# tviic2d6mddr register map
Vendor: Cypress Semiconductor; Series: tviic2d6mddr; File version: 1.0
CPU: CM7 r0p1, little endian, MPU, FPU, VTOR, 3 interrupt priority bits
Registers are 32-bit, read-write, reset 0x0 unless marked. A register's access mark holds for its fields unless they carry their own. Offsets are from the block's base; [hi:lo] are bit positions; lines under a group give offsets from that group; {n}, {i} and the like mark numbered series; 'fields as' and 'values as' point back to an identical list.

## VIDEOSS0 (part 17 of 18) — Video and Graphics Subsystem IP
Base 0x40A00000
0xF0000 INFRA group — AXI Infrastructure
  0x00 VRPU group — VRPU configuration.
    0x00 RD0_CTL ro — VRAM protection for read requests with ID=0 (not used).
      [9:8] PRIO
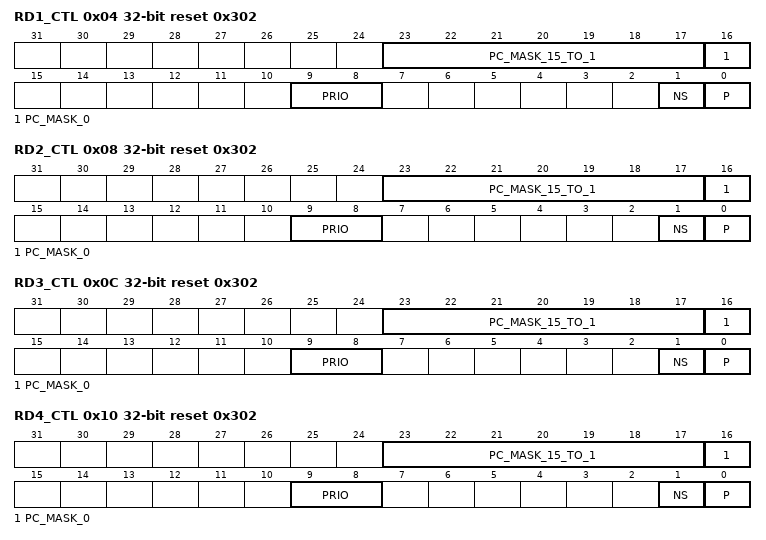
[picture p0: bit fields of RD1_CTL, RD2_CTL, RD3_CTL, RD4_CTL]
    0x04 RD1_CTL reset 0x302 — VRAM protection for read requests with ID=1 (fetchdecode0).
      [23:17] PC_MASK_15_TO_1 — Protection context mask for protection contexts '7' downto '1' (note: field name prefix '15_TO_1' is inconsistent due to backward compatibility). Bit PC_MASK_15_TO_1[i] indicates if the GFX_MPU_RDx RD_CTL.PC[3:0] protection context field can be set to the value 'i+1': - PC_MASK_15_TO_1[i] is '0': GFX_MPU_RDx RD_CTL.PC[3:0] can NOT be set to 'i+1'; and PC[3:0] is not changed. If the protection context of the write transfer is '0', protection is not applied and PC[3:0] can be changed. - PC_MASK_15_TO_1[i] is '1': GFX_MPU_RDx RD_CTL.PC[3:0] can be set to 'i+1'.
      [16] PC_MASK_0 ro — Protection context mask for protection context '0'. This field is a constant '0'.
      [9:8] PRIO — Device wide bus arbitration priority setting ('0': highest priority, '3': lowest priority). Masters with the same priority setting form a 'priority group'. Within a 'priority group', roundrobin arbitration is performed.
      [1] NS — Security setting ('0': secure mode; '1': non-secure mode).
      [0] P — Privileged setting ('0': user mode; '1': privileged mode).
    0x08 RD2_CTL reset 0x302 — VRAM protection for read requests with ID=2 (fetchlayer0).
      [23:17] PC_MASK_15_TO_1 — See RD1_CTL.PC_MASK_15_TO_1.
      [16] PC_MASK_0 ro — See RD1_CTL.PC_MASK_0.
      [9:8] PRIO — See RD1_CTL.PRIO.
      [1] NS — See RD1_CTL.NS.
      [0] P — See RD1_CTL.P.
    0x0C RD3_CTL reset 0x302 — VRAM protection for read requests with ID=3 (fetchwarp1).
      fields as INFRA.VRPU.RD2_CTL
    0x10 RD4_CTL reset 0x302 — VRAM protection for read requests with ID=4 (fetcheco1).
      fields as INFRA.VRPU.RD2_CTL
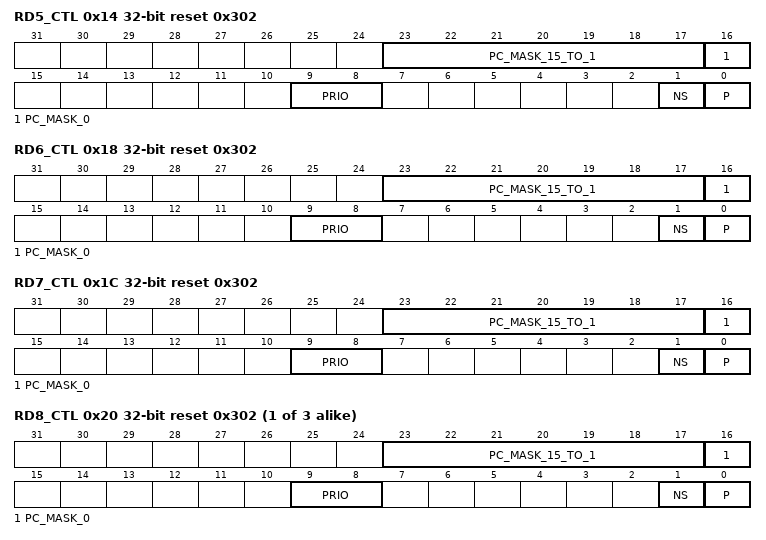
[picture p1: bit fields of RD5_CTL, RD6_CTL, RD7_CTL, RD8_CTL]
    0x14 RD5_CTL reset 0x302 — VRAM protection for read requests with ID=5 (fetcheco4).
      fields as INFRA.VRPU.RD2_CTL
    0x18 RD6_CTL reset 0x302 — VRAM protection for read requests with ID=6 (fetchlayer1).
      fields as INFRA.VRPU.RD2_CTL
    0x1C RD7_CTL reset 0x302 — VRAM protection for read requests with ID=7 (fetchdecode4).
      fields as INFRA.VRPU.RD2_CTL
    {0x0+4k} RD{k}_CTL reset 0x302 (k=8..10) — VRAM protection for read requests with ID={k} (fetchblit0/1/2).
      fields as INFRA.VRPU.RD2_CTL
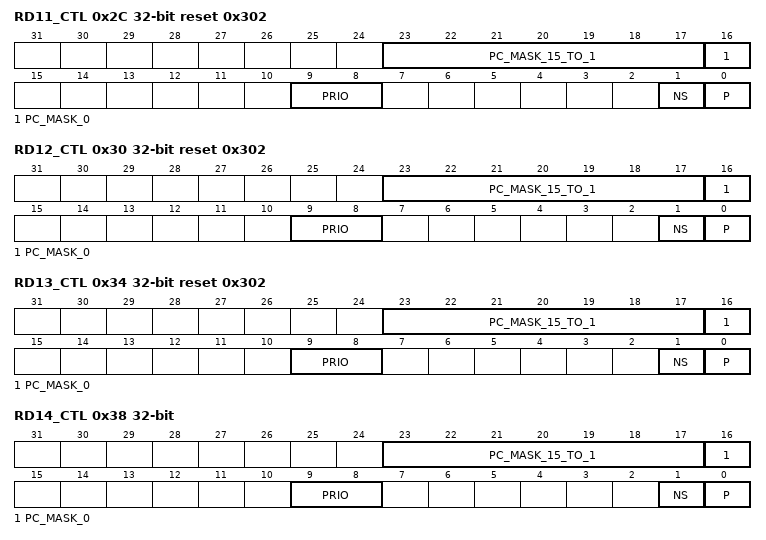
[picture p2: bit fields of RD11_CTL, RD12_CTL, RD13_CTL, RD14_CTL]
    0x2C RD11_CTL reset 0x302 — VRAM protection for read requests with ID=11 (cmdseqrd).
      fields as INFRA.VRPU.RD2_CTL
    0x30 RD12_CTL reset 0x302 — VRAM protection for read requests with ID=12 (drawengrd).
      fields as INFRA.VRPU.RD2_CTL
    0x34 RD13_CTL reset 0x302 — VRAM protection for read requests with ID=13 (jpegdecrd).
      fields as INFRA.VRPU.RD2_CTL
    0x38 RD14_CTL ro — VRAM protection for read requests with ID=14 (not used).
      [23:17] PC_MASK_15_TO_1, [16] PC_MASK_0, [9:8] PRIO, [1] NS, [0] P
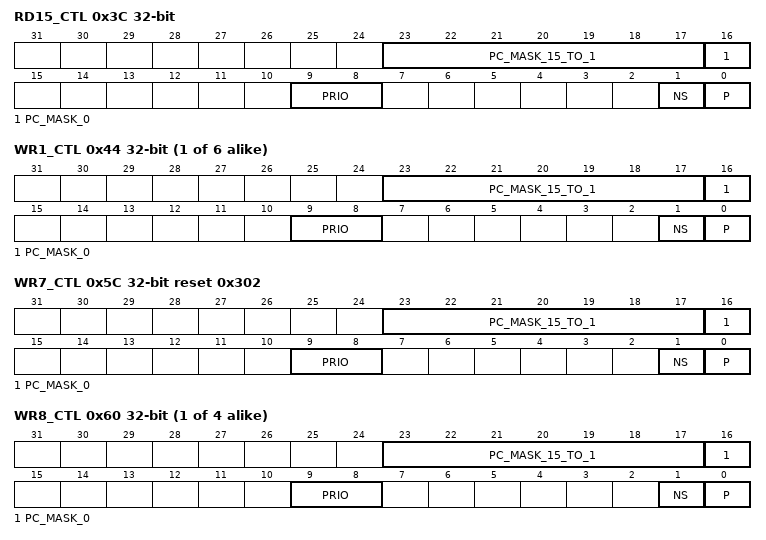
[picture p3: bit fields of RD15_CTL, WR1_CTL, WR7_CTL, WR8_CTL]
    0x3C RD15_CTL ro — VRAM protection for read requests with ID=15 (not used).
      [23:17] PC_MASK_15_TO_1, [16] PC_MASK_0, [9:8] PRIO, [1] NS, [0] P
    0x40 WR0_CTL ro — VRAM protection for write requests with ID=0 (not used).
      [9:8] PRIO
    {0x40+4k} WR{k}_CTL ro (k=1..6) — VRAM protection for write requests with ID={k} (not used).
      [23:17] PC_MASK_15_TO_1, [16] PC_MASK_0, [9:8] PRIO, [1] NS, [0] P
    0x5C WR7_CTL reset 0x302 — VRAM protection for write requests with ID=7 (jpegdecwr).
      [23:17] PC_MASK_15_TO_1 — Protection context mask for protection contexts '7' downto '1' (note: field name prefix '15_TO_1' is inconsistent due to backward compatibility). Bit PC_MASK_15_TO_1[i] indicates if the GFX_MPU_WRx WR_CTL.PC[3:0] protection context field can be set to the value 'i+1': - PC_MASK_15_TO_1[i] is '0': GFX_MPU_WRx WR_CTL.PC[3:0] can NOT be set to 'i+1'; and PC[3:0] is not changed. If the protection context of the write transfer is '0', protection is not applied and PC[3:0] can be changed. - PC_MASK_15_TO_1[i] is '1': GFX_MPU_WRx WR_CTL.PC[3:0] can be set to 'i+1'.
      [16] PC_MASK_0 ro — See RD1_CTL.PC_MASK_0.
      [9:8] PRIO — See RD1_CTL.PRIO.
      [1] NS — See RD1_CTL.NS.
      [0] P — See RD1_CTL.P.
    {0x40+4k} WR{k}_CTL ro (k=8..11) — VRAM protection for write requests with ID={k} (not used).
      [23:17] PC_MASK_15_TO_1, [16] PC_MASK_0, [9:8] PRIO, [1] NS, [0] P
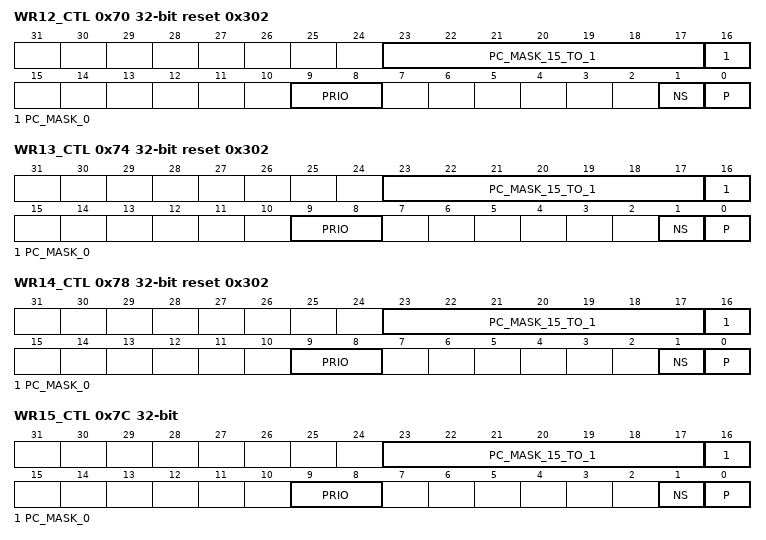
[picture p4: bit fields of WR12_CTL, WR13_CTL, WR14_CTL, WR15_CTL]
    0x70 WR12_CTL reset 0x302 — VRAM protection for write requests with ID=12 (drawengwr).
      [23:17] PC_MASK_15_TO_1 — See WR7_CTL.PC_MASK_15_TO_1.
      [16] PC_MASK_0 ro — See RD1_CTL.PC_MASK_0.
      [9:8] PRIO — See RD1_CTL.PRIO.
      [1] NS — See RD1_CTL.NS.
      [0] P — See RD1_CTL.P.
    0x74 WR13_CTL reset 0x302 — VRAM protection for write requests with ID=13 (store4).
      fields as INFRA.VRPU.WR12_CTL
    0x78 WR14_CTL reset 0x302 — VRAM protection for write requests with ID=14 (storeblit).
      fields as INFRA.VRPU.WR12_CTL
    0x7C WR15_CTL ro — VRAM protection for write requests with ID=15 (not used).
      [23:17] PC_MASK_15_TO_1, [16] PC_MASK_0, [9:8] PRIO, [1] NS, [0] P
  0x4000 GFX_MPU_RD0 group — MPU configuration for read master 0 (not used).
    0x00 RD_CTL ro — Memory protection context for AXI read requests (not used).
      [3:0] PC
  0x4400 GFX_MPU_RD1 group — MPU configuration for read master 1 (fetchdecode0).
    0x00 RD_CTL reset 0x7 — Memory protection context for AXI read requests.
      [3:0] PC — Active protection context. Modifications to this field are constrained by the associated RDx_CTL.PC_MASK_0 and RDx_CTL.PC_MASK_15_TO_1[] fields.
  0x4800 GFX_MPU_RD2 group — MPU configuration for read master 2 (fetchlayer0).
    0x00 RD_CTL reset 0x7 — Memory protection context for AXI read requests.
      fields as INFRA.GFX_MPU_RD1.RD_CTL
  0x4C00 GFX_MPU_RD3 group — MPU configuration for read master 3 (fetchwarp1).
    0x00 RD_CTL reset 0x7 — Memory protection context for AXI read requests.
      fields as INFRA.GFX_MPU_RD1.RD_CTL
  0x5000 GFX_MPU_RD4 group — MPU configuration for read master 4 (fetcheco1).
    0x00 RD_CTL reset 0x7 — Memory protection context for AXI read requests.
      fields as INFRA.GFX_MPU_RD1.RD_CTL
  0x5400 GFX_MPU_RD5 group — MPU configuration for read master 5 (fetcheco4).
    0x00 RD_CTL reset 0x7 — Memory protection context for AXI read requests.
      fields as INFRA.GFX_MPU_RD1.RD_CTL
  0x5800 GFX_MPU_RD6 group — MPU configuration for read master 6 (fetchlayer1).
    0x00 RD_CTL reset 0x7 — Memory protection context for AXI read requests.
      fields as INFRA.GFX_MPU_RD1.RD_CTL
  0x5C00 GFX_MPU_RD7 group — MPU configuration for read master 7 (fetchdecode4).
    0x00 RD_CTL reset 0x7 — Memory protection context for AXI read requests.
      fields as INFRA.GFX_MPU_RD1.RD_CTL
  {0x4000+0x400*j} GFX_MPU_RD{j} group (j=8..10) — MPU configuration for read master {j} (fetchblit0/1/2).
    0x00 RD_CTL reset 0x7 — Memory protection context for AXI read requests.
      fields as INFRA.GFX_MPU_RD1.RD_CTL
  0x6C00 GFX_MPU_RD11 group — MPU configuration for read master 11 (cmdseqrd).
    0x00 RD_CTL reset 0x7 — Memory protection context for AXI read requests.
      fields as INFRA.GFX_MPU_RD1.RD_CTL
  0x7000 GFX_MPU_RD12 group — MPU configuration for read master 12 (drawengrd).
    0x00 RD_CTL reset 0x7 — Memory protection context for AXI read requests.
      fields as INFRA.GFX_MPU_RD1.RD_CTL
  0x7400 GFX_MPU_RD13 group — MPU configuration for read master 13 (jpegdecrd).
    0x00 RD_CTL reset 0x7 — Memory protection context for AXI read requests.
      fields as INFRA.GFX_MPU_RD1.RD_CTL
  0x7800 GFX_MPU_RD14 group — MPU configuration for read master 14 (not used).
    0x00 RD_CTL ro — Memory protection context for AXI read requests (not used).
      [3:0] PC
  0x7C00 GFX_MPU_RD15 group — MPU configuration for read master 15 (not used).
    0x00 RD_CTL ro — Memory protection context for AXI read requests (not used).
      [3:0] PC
  {0x8000+0x400*j} GFX_MPU_WR{j} group (j=0..6) — MPU configuration for write master {j} (not used).
    0x00 WR_CTL ro — Memory protection context for AXI write requests (not used).
      [3:0] PC
  0x9C00 GFX_MPU_WR7 group — MPU configuration for write master 7 (jpegdecwr).
    0x00 WR_CTL reset 0x7 — Memory protection context for AXI write requests.
      [3:0] PC — Active protection context. Modifications to this field are constrained by the associated WRx_CTL.PC_MASK_0 and WRx_CTL.PC_MASK_15_TO_1[] fields.
  {0x8000+0x400*j} GFX_MPU_WR{j} group (j=8..11) — MPU configuration for write master {j} (not used).
    0x00 WR_CTL ro — Memory protection context for AXI write requests (not used).
      [3:0] PC
  0xB000 GFX_MPU_WR12 group — MPU configuration for write master 12 (drawengwr).
    0x00 WR_CTL reset 0x7 — Memory protection context for AXI write requests.
      fields as INFRA.GFX_MPU_WR7.WR_CTL
  0xB400 GFX_MPU_WR13 group — MPU configuration for write master 13 (store4).
    0x00 WR_CTL reset 0x7 — Memory protection context for AXI write requests.
      fields as INFRA.GFX_MPU_WR7.WR_CTL
  0xB800 GFX_MPU_WR14 group — MPU configuration for write master 14 (storeblit).
    0x00 WR_CTL reset 0x7 — Memory protection context for AXI write requests.
      fields as INFRA.GFX_MPU_WR7.WR_CTL
  0xBC00 GFX_MPU_WR15 group — MPU configuration for write master 15 (not used).
    0x00 WR_CTL ro — Memory protection context for AXI write requests (not used).
      [3:0] PC
